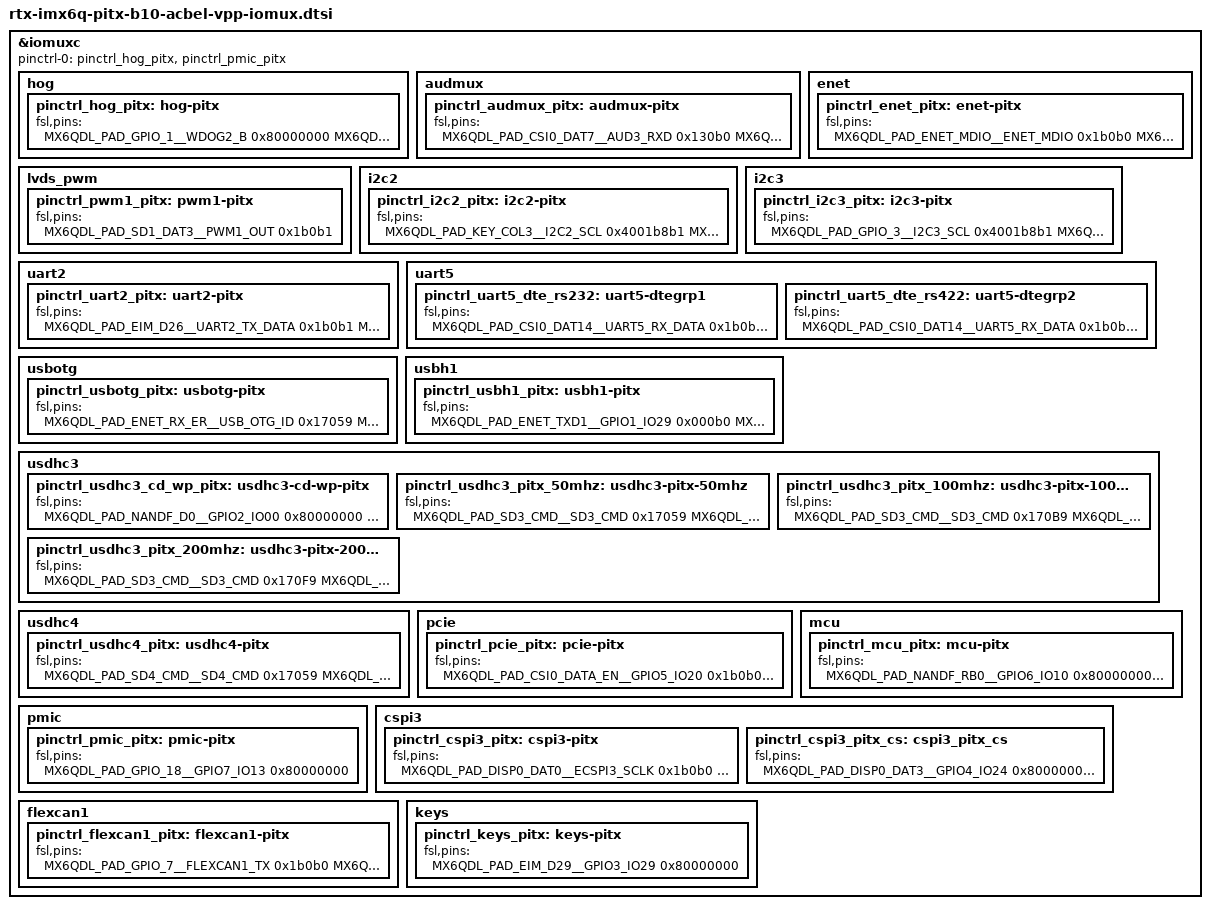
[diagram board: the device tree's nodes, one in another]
&iomuxc {
	pinctrl-names = "default";
	pinctrl-0 = <&pinctrl_hog_pitx &pinctrl_pmic_pitx>;

	hog {
		pinctrl_hog_pitx: hog-pitx {
			fsl,pins = <
				/* watchdog */
				MX6QDL_PAD_GPIO_1__WDOG2_B 				0x80000000	/* WDOG_B to reset pmic */
							
				MX6QDL_PAD_EIM_OE__GPIO2_IO25				0x80000000	/* USB_LAN_RESET_B */
				MX6QDL_PAD_EIM_D22__GPIO3_IO22				0x80000000	/* 3234_EN */
				MX6QDL_PAD_NANDF_CS3__GPIO6_IO16			0x80000000	/* UART5_TM */
				MX6QDL_PAD_NANDF_ALE__GPIO6_IO08			0x80000000	/* UART5_M1 */
				MX6QDL_PAD_NANDF_CLE__GPIO6_IO07			0x80000000	/* UART5_M0 */				
				
				/* LVDS */
				MX6QDL_PAD_SD1_DAT2__GPIO1_IO19				0x80000000	/* LVDS_BLEN */
				
				/* GPIO */
				MX6QDL_PAD_EIM_A25__GPIO5_IO02				0x1f0b0	/* GPIO0 (in)*/
				MX6QDL_PAD_EIM_D18__GPIO3_IO18				0x1f0b0	/* GPIO1 (in)*/
				MX6QDL_PAD_EIM_D23__GPIO3_IO23				0x80000000	/* GPIO2 (out)*/
				MX6QDL_PAD_CSI0_DAT10__GPIO5_IO28			0x80000000	/* GPIO3 (out)*/
				MX6QDL_PAD_EIM_D20__GPIO3_IO20				0x80000000	/* GPIO4 */
				MX6QDL_PAD_CSI0_DAT11__GPIO5_IO29			0x80000000	/* GPIO5 */
				MX6QDL_PAD_EIM_D24__GPIO3_IO24				0x80000000	/* GPIO6 */
				MX6QDL_PAD_EIM_D19__GPIO3_IO19				0x80000000	/* GPIO7 */
				
				/* Audio Codec */
				MX6QDL_PAD_GPIO_0__CCM_CLKO1				0x130b0		/* SGTL5000 sys_mclk */
				MX6QDL_PAD_SD3_RST__GPIO7_IO08				0x80000000	/* HEADPHONE_DET */
				MX6QDL_PAD_GPIO_9__GPIO1_IO09				0x80000000	/* MICROPHONE_DET */
				MX6QDL_PAD_KEY_COL2__GPIO4_IO10				0x80000000	/* AUD_AMP_STBY_B */

			>;
		};
	};

	audmux {
		pinctrl_audmux_pitx: audmux-pitx {
			fsl,pins = <
				MX6QDL_PAD_CSI0_DAT7__AUD3_RXD				0x130b0
				MX6QDL_PAD_CSI0_DAT4__AUD3_TXC				0x130b0
				MX6QDL_PAD_CSI0_DAT5__AUD3_TXD				0x110b0
				MX6QDL_PAD_CSI0_DAT6__AUD3_TXFS				0x130b0
			>;
		};
	};

	enet {
		pinctrl_enet_pitx: enet-pitx {
			fsl,pins = <
				MX6QDL_PAD_ENET_MDIO__ENET_MDIO				0x1b0b0			/* RGMII_MDIO */
				MX6QDL_PAD_ENET_MDC__ENET_MDC				0x1b0b0			/* RGMII_MDC */
				MX6QDL_PAD_RGMII_TXC__RGMII_TXC				0x1b0b0
				MX6QDL_PAD_RGMII_TD0__RGMII_TD0				0x1b0b0
				MX6QDL_PAD_RGMII_TD1__RGMII_TD1				0x1b0b0
				MX6QDL_PAD_RGMII_TD2__RGMII_TD2				0x1b0b0
				MX6QDL_PAD_RGMII_TD3__RGMII_TD3				0x1b0b0
				MX6QDL_PAD_RGMII_TX_CTL__RGMII_TX_CTL			0x1b0b0
				MX6QDL_PAD_ENET_REF_CLK__ENET_TX_CLK			0x4001b0a8		/* ENET_REFCLK */
				MX6QDL_PAD_RGMII_RXC__RGMII_RXC				0x1b0b0
				MX6QDL_PAD_RGMII_RD0__RGMII_RD0				0x1b0b0
				MX6QDL_PAD_RGMII_RD1__RGMII_RD1				0x1b0b0
				MX6QDL_PAD_RGMII_RD2__RGMII_RD2				0x1b0b0
				MX6QDL_PAD_RGMII_RD3__RGMII_RD3				0x1b0b0
				MX6QDL_PAD_RGMII_RX_CTL__RGMII_RX_CTL			0x1b0b0
				MX6QDL_PAD_ENET_RXD1__GPIO1_IO26			0x000b1			/* RGMII_INT */
				MX6QDL_PAD_ENET_CRS_DV__GPIO1_IO25			0x1b0b0			/* RGMII_nRST */
			>;
		};
	};
	
	lvds_pwm {
		pinctrl_pwm1_pitx: pwm1-pitx {
			fsl,pins = <
				MX6QDL_PAD_SD1_DAT3__PWM1_OUT				0x1b0b1		/* LVDS_BLT_CTRL PWM */
			>;
		};
	};
	
	i2c2 {
		pinctrl_i2c2_pitx: i2c2-pitx {
			fsl,pins = <
				MX6QDL_PAD_KEY_COL3__I2C2_SCL			0x4001b8b1
				MX6QDL_PAD_KEY_ROW3__I2C2_SDA			0x4001b8b1
			>;
		};
	};

	i2c3 {
		pinctrl_i2c3_pitx: i2c3-pitx {
			fsl,pins = <
				MX6QDL_PAD_GPIO_3__I2C3_SCL			0x4001b8b1
				MX6QDL_PAD_GPIO_6__I2C3_SDA			0x4001b8b1
			>;
		};
	};

	uart2 {
		pinctrl_uart2_pitx: uart2-pitx {
			fsl,pins = <
				MX6QDL_PAD_EIM_D26__UART2_TX_DATA		0x1b0b1
				MX6QDL_PAD_EIM_D27__UART2_RX_DATA		0x1b0b1
			>;
		};
	};


	uart5 {
		/* DTE mode */
		pinctrl_uart5_dte_rs232: uart5-dtegrp1 {
			fsl,pins = <
				MX6QDL_PAD_CSI0_DAT14__UART5_RX_DATA	0x1b0b1
				MX6QDL_PAD_CSI0_DAT15__UART5_TX_DATA	0x1b0b1
				MX6QDL_PAD_KEY_ROW4__UART5_RTS_B		0x1b0b1
				MX6QDL_PAD_KEY_COL4__UART5_CTS_B		0x1b0b1
			>;
		};
		pinctrl_uart5_dte_rs422: uart5-dtegrp2 {
			fsl,pins = <
				MX6QDL_PAD_CSI0_DAT14__UART5_RX_DATA	0x1b0b1
				MX6QDL_PAD_CSI0_DAT15__UART5_TX_DATA	0x1b0b1
				MX6QDL_PAD_KEY_ROW4__UART5_RTS_B		0x1b0b1
				MX6QDL_PAD_KEY_COL4__GPIO4_IO14			0x80000000
			>;
		};
	};


	usbotg {
		pinctrl_usbotg_pitx: usbotg-pitx {
			fsl,pins = <
				MX6QDL_PAD_ENET_RX_ER__USB_OTG_ID			0x17059
				MX6QDL_PAD_GPIO_19__GPIO4_IO05				0x80000000	/* USB_OTG_PWR_EN */
				MX6QDL_PAD_EIM_D21__USB_OTG_OC				0x1b0b0		/* USB_OTG_OC */
			>;
		};
	};

	usbh1 {
		pinctrl_usbh1_pitx: usbh1-pitx {
			fsl,pins = <
				MX6QDL_PAD_ENET_TXD1__GPIO1_IO29			0x000b0		/* USB_H1_PWR_EN */
				MX6QDL_PAD_EIM_D30__USB_H1_OC				0x1b0b0		/* USB_H1_OC */
				MX6QDL_PAD_EIM_CS0__GPIO2_IO23				0x80000000	/* USB_HUB_RESET_B */
			>;
		};
	};

	usdhc3 {
		pinctrl_usdhc3_cd_wp_pitx: usdhc3-cd-wp-pitx {
			fsl,pins = <
				MX6QDL_PAD_NANDF_D0__GPIO2_IO00				0x80000000	/* SD3_CD */
				MX6QDL_PAD_NANDF_D1__GPIO2_IO01				0x80000000	/* SD3_WP */
			>;
		};
		
		pinctrl_usdhc3_pitx_50mhz: usdhc3-pitx-50mhz {						/* 50Mhz */
			fsl,pins = <
				MX6QDL_PAD_SD3_CMD__SD3_CMD				0x17059
				MX6QDL_PAD_SD3_CLK__SD3_CLK				0x10059
				MX6QDL_PAD_SD3_DAT0__SD3_DATA0				0x17059
				MX6QDL_PAD_SD3_DAT1__SD3_DATA1				0x17059
				MX6QDL_PAD_SD3_DAT2__SD3_DATA2				0x17059
				MX6QDL_PAD_SD3_DAT3__SD3_DATA3				0x17059

			>;
		};

		pinctrl_usdhc3_pitx_100mhz: usdhc3-pitx-100mhz { 					/* 100Mhz */
			fsl,pins = <
				MX6QDL_PAD_SD3_CMD__SD3_CMD				0x170B9
				MX6QDL_PAD_SD3_CLK__SD3_CLK				0x100B9
				MX6QDL_PAD_SD3_DAT0__SD3_DATA0				0x170B9
				MX6QDL_PAD_SD3_DAT1__SD3_DATA1				0x170B9
				MX6QDL_PAD_SD3_DAT2__SD3_DATA2				0x170B9
				MX6QDL_PAD_SD3_DAT3__SD3_DATA3				0x170B9
			>;
		};

		pinctrl_usdhc3_pitx_200mhz: usdhc3-pitx-200mhz { 					/* 200Mhz */
			fsl,pins = <
				MX6QDL_PAD_SD3_CMD__SD3_CMD				0x170F9
				MX6QDL_PAD_SD3_CLK__SD3_CLK				0x100F9
				MX6QDL_PAD_SD3_DAT0__SD3_DATA0				0x170F9
				MX6QDL_PAD_SD3_DAT1__SD3_DATA1				0x170F9
				MX6QDL_PAD_SD3_DAT2__SD3_DATA2				0x170F9
				MX6QDL_PAD_SD3_DAT3__SD3_DATA3				0x170F9
				MX6QDL_PAD_SD3_DAT4__SD3_DATA4				0x170F9
				MX6QDL_PAD_SD3_DAT5__SD3_DATA5				0x170F9
				MX6QDL_PAD_SD3_DAT6__SD3_DATA6				0x170F9
				MX6QDL_PAD_SD3_DAT7__SD3_DATA7				0x170F9
			>;
		};
	};

	usdhc4 {
		pinctrl_usdhc4_pitx: usdhc4-pitx {
			fsl,pins = <
				MX6QDL_PAD_SD4_CMD__SD4_CMD				0x17059
				MX6QDL_PAD_SD4_CLK__SD4_CLK				0x10059
				MX6QDL_PAD_SD4_DAT0__SD4_DATA0				0x17059
				MX6QDL_PAD_SD4_DAT1__SD4_DATA1				0x17059
				MX6QDL_PAD_SD4_DAT2__SD4_DATA2				0x17059
				MX6QDL_PAD_SD4_DAT3__SD4_DATA3				0x17059
				MX6QDL_PAD_SD4_DAT4__SD4_DATA4				0x17059
				MX6QDL_PAD_SD4_DAT5__SD4_DATA5				0x17059
				MX6QDL_PAD_SD4_DAT6__SD4_DATA6				0x17059
				MX6QDL_PAD_SD4_DAT7__SD4_DATA7				0x17059
			>;
		};
	};

	pcie {
		pinctrl_pcie_pitx: pcie-pitx {
			fsl,pins = <
				MX6QDL_PAD_CSI0_DATA_EN__GPIO5_IO20			0x1b0b0		/* PCIE_WAKE_B */
				MX6QDL_PAD_GPIO_16__GPIO7_IO11				0x1b0b0		/* PCIE_DIS_B */
				MX6QDL_PAD_GPIO_17__GPIO7_IO12				0x1b0b0		/* PCIE_RST */
			>;
		};
	};

	mcu {
		pinctrl_mcu_pitx: mcu-pitx {
			fsl,pins = <
				MX6QDL_PAD_NANDF_RB0__GPIO6_IO10			0x80000000	/* MCU Reset */
				MX6QDL_PAD_NANDF_WP_B__GPIO6_IO09			0x80000000	/* MCU_UPDATE_PWR_ON */
				MX6QDL_PAD_NANDF_CS0__GPIO6_IO11			0x80000000	/* MCU_BOOT_EN */
				MX6QDL_PAD_EIM_D31__GPIO3_IO31				0x80000000	/* MCU_INT */
			>;
		};
	};

	pmic {
		pinctrl_pmic_pitx: pmic-pitx {
			fsl,pins = <
				MX6QDL_PAD_GPIO_18__GPIO7_IO13				0x80000000	/* PMIC INT */
			>;
		};
	};

	cspi3 {
		pinctrl_cspi3_pitx: cspi3-pitx {
			fsl,pins = <
				MX6QDL_PAD_DISP0_DAT0__ECSPI3_SCLK			0x1b0b0		/* CSPI3_CLK */
				MX6QDL_PAD_DISP0_DAT1__ECSPI3_MOSI			0x1b0b0		/* CSPI3_MOSI */
				MX6QDL_PAD_DISP0_DAT2__ECSPI3_MISO			0x1b0b0		/* CSPI3_MISO */
			>;
		};
		
		pinctrl_cspi3_pitx_cs: cspi3_pitx_cs{
			fsl,pins = <

                MX6QDL_PAD_DISP0_DAT3__GPIO4_IO24           0x80000000	/* CSPI3_CS0 */
                MX6QDL_PAD_CSI0_DAT8__GPIO5_IO26			0x80000000	/* CSPI3_CS1 */
                MX6QDL_PAD_CSI0_DAT9__GPIO5_IO27			0x80000000	/* CSPI3_CS2 */
                MX6QDL_PAD_EIM_D25__GPIO3_IO25				0x80000000	/* CSPI3_CS3 */
            >;		
		};
	};
	
	flexcan1 {
		pinctrl_flexcan1_pitx: flexcan1-pitx {
			fsl,pins = <
				MX6QDL_PAD_GPIO_7__FLEXCAN1_TX				0x1b0b0		/* CAN1_TX */
				MX6QDL_PAD_GPIO_8__FLEXCAN1_RX				0x1b0b0		/* CAN1_RX */
				MX6QDL_PAD_GPIO_5__GPIO1_IO05				0x1b0b0		/* CAN1_STBY */
			>;
		};
	};
	
	keys {
		pinctrl_keys_pitx: keys-pitx {
			fsl,pins = <	
					/* special key */
				MX6QDL_PAD_EIM_D29__GPIO3_IO29				0x80000000	/* PWR_BTN_SNS */
			>;
		};
	};		
};
